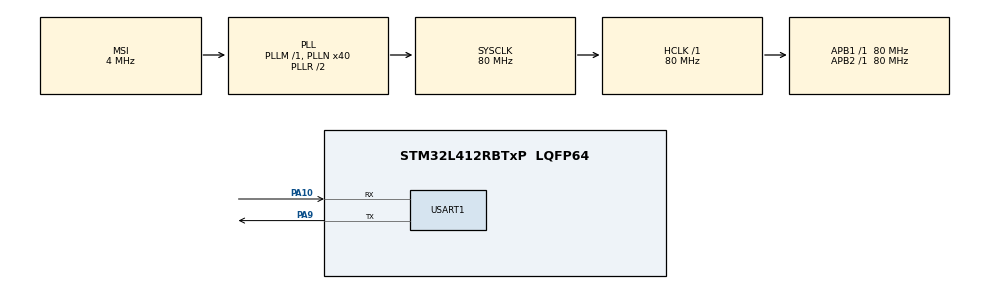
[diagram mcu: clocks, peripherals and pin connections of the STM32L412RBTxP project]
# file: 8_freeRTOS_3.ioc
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FREERTOS.Tasks01=defaultTask,0,128,StartDefaultTask,Default,NULL,Dynamic,NULL,NULL
Mcu.Family=STM32L4
Mcu.Name=STM32L412RBTxP
Mcu.Package=LQFP64
NVIC.PriorityGroup=NVIC_PRIORITYGROUP_4
NVIC.TIM6_IRQn=true\:0\:0\:false\:false\:true\:false\:false\:true
NVIC.TimeBase=TIM6_IRQn
NVIC.TimeBaseIP=TIM6
PA10.Mode=Asynchronous
PA10.Signal=USART1_RX
PA9.Mode=Asynchronous
PA9.Signal=USART1_TX
ProjectManager.HeapSize=0x200
ProjectManager.StackSize=0x400
ProjectManager.TargetToolchain=STM32CubeIDE
RCC.ADCFreq_Value=80000000
RCC.AHBFreq_Value=80000000
RCC.APB1Freq_Value=80000000
RCC.APB1TimFreq_Value=80000000
RCC.APB2Freq_Value=80000000
RCC.APB2TimFreq_Value=80000000
RCC.CortexFreq_Value=80000000
RCC.HCLKFreq_Value=80000000
RCC.HSE_VALUE=8000000
RCC.HSI48_VALUE=48000000
RCC.HSI_VALUE=16000000
RCC.LSE_VALUE=32768
RCC.MSI_VALUE=4000000
RCC.PLLN=40
RCC.SYSCLKFreq_VALUE=80000000
RCC.SYSCLKSource=RCC_SYSCLKSOURCE_PLLCLK
RCC.USBFreq_Value=4000000
RCC.VCOOutputFreq_Value=160000000
USART1.VirtualMode-Asynchronous=VM_ASYNC
VP_FREERTOS_VS_CMSIS_V1.Mode=CMSIS_V1
VP_SYS_VS_tim6.Mode=TIM6
board=custom

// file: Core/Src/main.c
/* USER CODE BEGIN Header */
/**
  ******************************************************************************
  * @file           : main.c
  * @brief          : Main program body
  ******************************************************************************
  * @attention
  *
  * <h2><center>&copy; Copyright (c) 2021 STMicroelectronics.
  * All rights reserved.</center></h2>
  *
  * This software component is licensed by ST under BSD 3-Clause license,
  * the "License"; You may not use this file except in compliance with the
  * License. You may obtain a copy of the License at:
  *                        opensource.org/licenses/BSD-3-Clause
  *
  ******************************************************************************
  */
/* USER CODE END Header */
#include "main.h"
#include "cmsis_os.h"
#include "usart.h"
#include "gpio.h"

/* USER CODE BEGIN PM */

#ifdef __GNUC__
    #define PUTCHAR_PROTOTYPE int __io_putchar(int ch)
#else
    #define PUTCHAR_PROTOTYPE int fputc(int ch, FILE *f)
#endif

PUTCHAR_PROTOTYPE
{
  HAL_UART_Transmit(&huart1, (uint8_t *)&ch, 1, 0xFFFF);
  return ch;
}

/* USER CODE END PM */

void SystemClock_Config(void);
void MX_FREERTOS_Init(void);

int main(void)
{

  /* MCU Configuration--------------------------------------------------------*/

  /* Reset of all peripherals, Initializes the Flash interface and the Systick. */
  HAL_Init();

  /* Configure the system clock */
  SystemClock_Config();

  /* Initialize all configured peripherals */
  MX_GPIO_Init();
  MX_USART1_UART_Init();

  /* Call init function for freertos objects (in freertos.c) */
  MX_FREERTOS_Init();
  /* Start scheduler */
  osKernelStart();

  /* We should never get here as control is now taken by the scheduler */
  /* Infinite loop */
  while (1)
  {

  }
}

void SystemClock_Config(void)
{
  RCC_OscInitTypeDef RCC_OscInitStruct = {0};
  RCC_ClkInitTypeDef RCC_ClkInitStruct = {0};
  RCC_PeriphCLKInitTypeDef PeriphClkInit = {0};

  /** Configure the main internal regulator output voltage
  */
  if (HAL_PWREx_ControlVoltageScaling(PWR_REGULATOR_VOLTAGE_SCALE1) != HAL_OK)
  {
    Error_Handler();
  }
  /** Initializes the RCC Oscillators according to the specified parameters
  * in the RCC_OscInitTypeDef structure.
  */
  RCC_OscInitStruct.OscillatorType = RCC_OSCILLATORTYPE_MSI;
  RCC_OscInitStruct.MSIState = RCC_MSI_ON;
  RCC_OscInitStruct.MSICalibrationValue = 0;
  RCC_OscInitStruct.MSIClockRange = RCC_MSIRANGE_6;
  RCC_OscInitStruct.PLL.PLLState = RCC_PLL_ON;
  RCC_OscInitStruct.PLL.PLLSource = RCC_PLLSOURCE_MSI;
  RCC_OscInitStruct.PLL.PLLM = 1;
  RCC_OscInitStruct.PLL.PLLN = 40;
  RCC_OscInitStruct.PLL.PLLQ = RCC_PLLQ_DIV2;
  RCC_OscInitStruct.PLL.PLLR = RCC_PLLR_DIV2;
  if (HAL_RCC_OscConfig(&RCC_OscInitStruct) != HAL_OK)
  {
    Error_Handler();
  }
  /** Initializes the CPU, AHB and APB buses clocks
  */
  RCC_ClkInitStruct.ClockType = RCC_CLOCKTYPE_HCLK|RCC_CLOCKTYPE_SYSCLK
                              |RCC_CLOCKTYPE_PCLK1|RCC_CLOCKTYPE_PCLK2;
  RCC_ClkInitStruct.SYSCLKSource = RCC_SYSCLKSOURCE_PLLCLK;
  RCC_ClkInitStruct.AHBCLKDivider = RCC_SYSCLK_DIV1;
  RCC_ClkInitStruct.APB1CLKDivider = RCC_HCLK_DIV1;
  RCC_ClkInitStruct.APB2CLKDivider = RCC_HCLK_DIV1;

  if (HAL_RCC_ClockConfig(&RCC_ClkInitStruct, FLASH_LATENCY_4) != HAL_OK)
  {
    Error_Handler();
  }
  PeriphClkInit.PeriphClockSelection = RCC_PERIPHCLK_USART1;
  PeriphClkInit.Usart1ClockSelection = RCC_USART1CLKSOURCE_PCLK2;
  if (HAL_RCCEx_PeriphCLKConfig(&PeriphClkInit) != HAL_OK)
  {
    Error_Handler();
  }
}

 /**
  * @brief  Period elapsed callback in non blocking mode
  * @note   This function is called  when TIM6 interrupt took place, inside
  * HAL_TIM_IRQHandler(). It makes a direct call to HAL_IncTick() to increment
  * a global variable "uwTick" used as application time base.
  * @param  htim : TIM handle
  * @retval None
  */
void HAL_TIM_PeriodElapsedCallback(TIM_HandleTypeDef *htim)
{
  if (htim->Instance == TIM6) {
    HAL_IncTick();
  }
}

void Error_Handler(void)
{
  __disable_irq();
  while (1)
  {
  }
}

/************************ (C) COPYRIGHT STMicroelectronics *****END OF FILE****/

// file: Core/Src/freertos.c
/* USER CODE BEGIN Header */
/**
  ******************************************************************************
  * File Name          : freertos.c
  * Description        : Code for freertos applications
  ******************************************************************************
  * @attention
  *
  * <h2><center>&copy; Copyright (c) 2021 STMicroelectronics.
  * All rights reserved.</center></h2>
  *
  * This software component is licensed by ST under Ultimate Liberty license
  * SLA0044, the "License"; You may not use this file except in compliance with
  * the License. You may obtain a copy of the License at:
  *                             www.st.com/SLA0044
  *
  ******************************************************************************
  */
/* USER CODE END Header */

#include "FreeRTOS.h"
#include "task.h"
#include "main.h"
#include "cmsis_os.h"

/* USER CODE BEGIN Includes */
#include <stdio.h>
/* USER CODE END Includes */

/* USER CODE BEGIN PTD */
typedef enum
{
  eNotifyNone,
  eNotifyFlashInitialized,
} eNotifyValue;

/* USER CODE END PTD */

/* USER CODE BEGIN PD */

#define mode 0

/* USER CODE END PD */

/* USER CODE BEGIN Variables */
SemaphoreHandle_t MutexHandle;

TaskHandle_t MyNotifyTaskHandle_1 = NULL;
TaskHandle_t MyPrintTaskHandle = NULL;

/* USER CODE END Variables */
osThreadId defaultTaskHandle;

/* USER CODE BEGIN FunctionPrototypes */
void GetMutexTask_1();
void GetMutexTask_2();

void NotifyTask_1();
void printTask();
//void vCall_TaskNotify(eNotifyValue eNofiValue);
/* USER CODE END FunctionPrototypes */

void StartDefaultTask(void const * argument);

void MX_FREERTOS_Init(void); /* (MISRA C 2004 rule 8.1) */

/* GetIdleTaskMemory prototype (linked to static allocation support) */
void vApplicationGetIdleTaskMemory( StaticTask_t **ppxIdleTaskTCBBuffer, StackType_t **ppxIdleTaskStackBuffer, uint32_t *pulIdleTaskStackSize );

/* USER CODE BEGIN GET_IDLE_TASK_MEMORY */
static StaticTask_t xIdleTaskTCBBuffer;
static StackType_t xIdleStack[configMINIMAL_STACK_SIZE];

void vApplicationGetIdleTaskMemory( StaticTask_t **ppxIdleTaskTCBBuffer, StackType_t **ppxIdleTaskStackBuffer, uint32_t *pulIdleTaskStackSize )
{
  *ppxIdleTaskTCBBuffer = &xIdleTaskTCBBuffer;
  *ppxIdleTaskStackBuffer = &xIdleStack[0];
  *pulIdleTaskStackSize = configMINIMAL_STACK_SIZE;
  /* place for user code */
}
/* USER CODE END GET_IDLE_TASK_MEMORY */

void MX_FREERTOS_Init(void) {

  /* Create the thread(s) */
  /* definition and creation of defaultTask */
  osThreadDef(defaultTask, StartDefaultTask, osPriorityNormal, 0, 128);
  defaultTaskHandle = osThreadCreate(osThread(defaultTask), NULL);

  /* USER CODE BEGIN RTOS_THREADS */
  /* add threads, ... */
#if mode
  MutexHandle = xSemaphoreCreateMutex();
  xTaskCreate(GetMutexTask_1, "GetMutex_1" , configMINIMAL_STACK_SIZE, NULL, 1, NULL);
  xTaskCreate(GetMutexTask_2, "GetMutex_2" , configMINIMAL_STACK_SIZE, NULL, 1, NULL);

#else
  xTaskCreate(NotifyTask_1, "notify_1" , configMINIMAL_STACK_SIZE, NULL, 1, &MyNotifyTaskHandle_1);
  xTaskCreate(printTask, "printtt" , configMINIMAL_STACK_SIZE, NULL, 1, &MyPrintTaskHandle);
#endif
  //xTaskCreate(NotifyTask, "Notify" , configMINIMAL_STACK_SIZE, NULL, 1, &MyNotifyTaskHandle);

  /* USER CODE END RTOS_THREADS */

}

void StartDefaultTask(void const * argument)
{
  for(;;)
  {
    osDelay(1);
  }
}

/* USER CODE BEGIN Application */
#if mode
void GetMutexTask_1()
{
  /* Infinite loop */
  for (;;)
  {
    vTaskDelay(1000);
    if (xSemaphoreTake(MutexHandle, 500) == pdTRUE)
    {
      printf("Task1 get mutex while 2sec. \r\n");
      vTaskDelay(2000);
      xSemaphoreGive(MutexHandle);
    }
    else
    {
      printf("Task1 mutex timeout or error \r\n");
    }
  }
}
void GetMutexTask_2()
{
  /* Infinite loop */
  for (;;)
  {
    vTaskDelay(1000);
    if (xSemaphoreTake(MutexHandle, 500) == pdTRUE)
    {
      printf("Task2 get mutex while 1.5sec.\r\n");
      vTaskDelay(1500);
      xSemaphoreGive(MutexHandle);

    }
    else
    {
      printf("Task2 mutex timeout or error \r\n");
      vCall_TaskNotify(eNotifyFlashInitialized);

    }
  }
}
#else

void NotifyTask_1()
{
  uint8_t cnt=0;

  for (;;)
  {
    cnt++;
    printf("task1 \r\n");
    vTaskDelay(1000);
    if (cnt==5)
    {
      xTaskNotify(MyPrintTaskHandle, eNotifyFlashInitialized, eSetValueWithOverwrite);
    }
  }
}

void printTask()
{
  ulTaskNotifyTake( pdTRUE, portMAX_DELAY );
  for (;;)
  {
    printf("cnt is over 5 \r\n");
    vTaskDelay(1000);
  }
}

#endif

/* USER CODE END Application */

/************************ (C) COPYRIGHT STMicroelectronics *****END OF FILE****/
